AUTOSAR XML (schema 4-2-2)
package /ComponentTypes
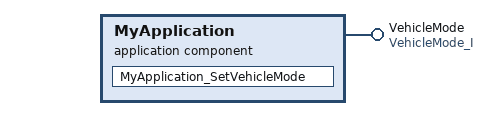
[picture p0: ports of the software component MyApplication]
  application sw component type MyApplication
    provide port VehicleMode: mode-switch-sender-com-spec{enhanced-mode-api=false, mode-group=mode, mode-switched-ack=timeout=0.01, queue-length=1}, provided-interface=VehicleMode_I
    behavior MyApplication_InternalBehavior: port-api-option{enable-take-address=false, indirect-api=false, port=VehicleMode}
      runnable MyApplication_SetVehicleMode: mode-access-point=VehicleMode.mode
        mode switch point SWITCH_VehicleMode_mode: mode-group=VehicleMode.mode
  swc implementation MyApplication_Implementation: behavior=MyApplication_InternalBehavior
